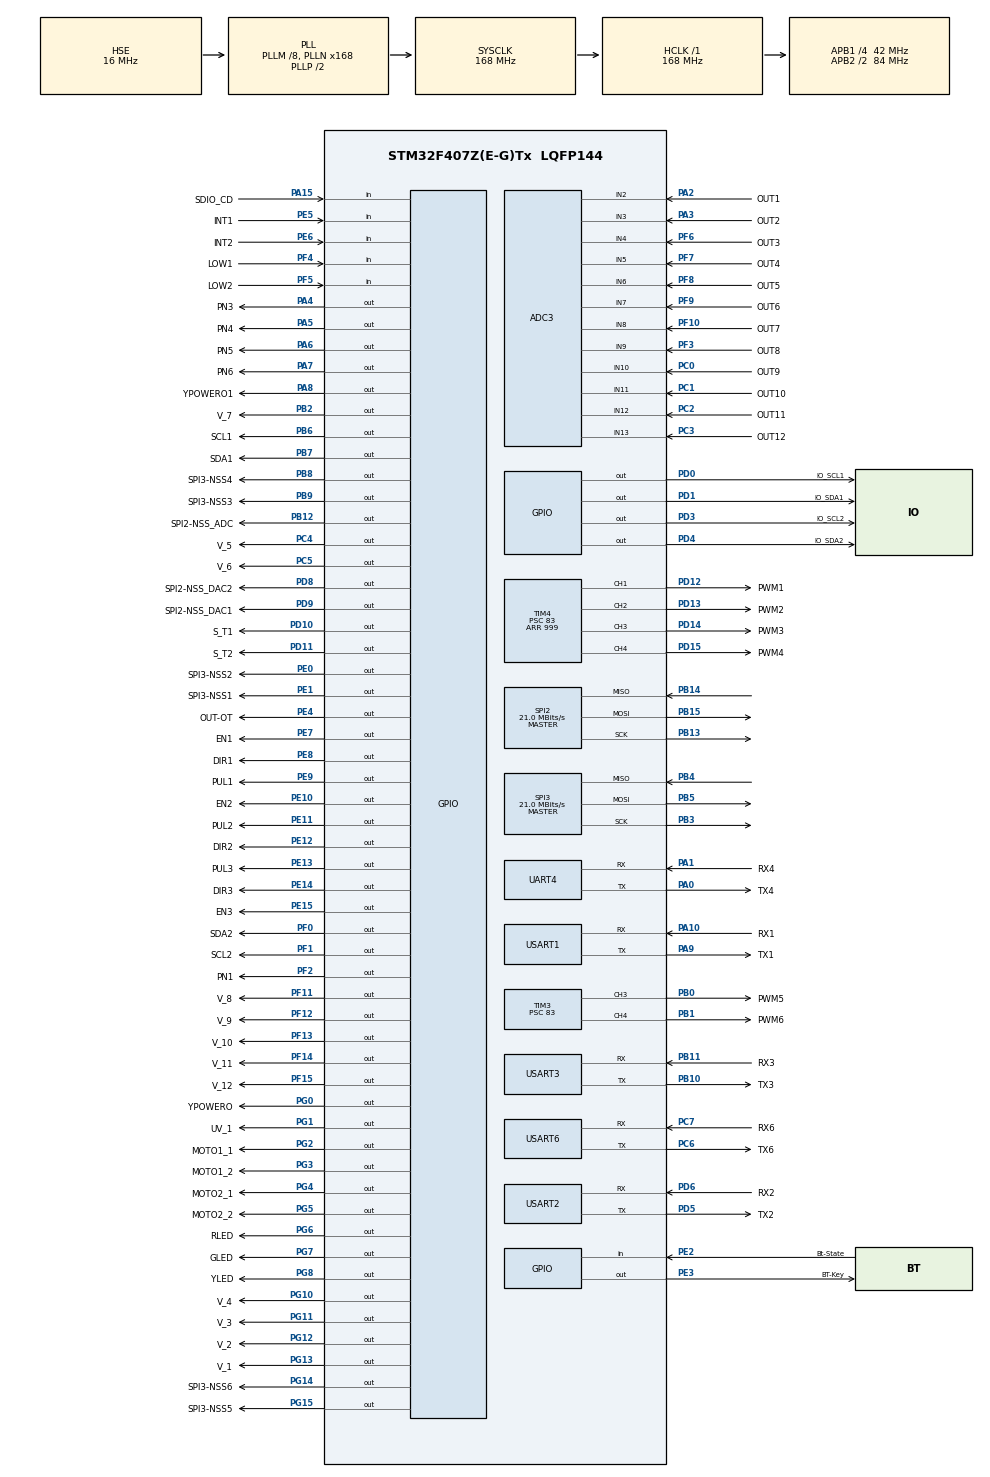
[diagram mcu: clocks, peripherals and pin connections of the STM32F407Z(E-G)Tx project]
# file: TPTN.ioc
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ADC3.Channel-0\#ChannelRegularConversion=ADC_CHANNEL_2
ADC3.Channel-1\#ChannelRegularConversion=ADC_CHANNEL_3
ADC3.Channel-10\#ChannelRegularConversion=ADC_CHANNEL_12
ADC3.Channel-11\#ChannelRegularConversion=ADC_CHANNEL_13
ADC3.Channel-2\#ChannelRegularConversion=ADC_CHANNEL_4
ADC3.Channel-3\#ChannelRegularConversion=ADC_CHANNEL_5
ADC3.Channel-4\#ChannelRegularConversion=ADC_CHANNEL_6
ADC3.Channel-5\#ChannelRegularConversion=ADC_CHANNEL_7
ADC3.Channel-6\#ChannelRegularConversion=ADC_CHANNEL_8
ADC3.Channel-7\#ChannelRegularConversion=ADC_CHANNEL_9
ADC3.Channel-8\#ChannelRegularConversion=ADC_CHANNEL_10
ADC3.Channel-9\#ChannelRegularConversion=ADC_CHANNEL_11
ADC3.DMAContinuousRequests=ENABLE
ADC3.DiscontinuousConvMode=DISABLE
ADC3.EOCSelection=ADC_EOC_SEQ_CONV
ADC3.ExternalTrigConv=ADC_EXTERNALTRIGCONV_T2_TRGO
ADC3.InjNumberOfConversion=0
ADC3.NbrOfConversion=12
ADC3.NbrOfConversionFlag=1
ADC3.Rank-0\#ChannelRegularConversion=1
ADC3.Rank-1\#ChannelRegularConversion=2
ADC3.Rank-10\#ChannelRegularConversion=11
ADC3.Rank-11\#ChannelRegularConversion=12
ADC3.Rank-2\#ChannelRegularConversion=3
ADC3.Rank-3\#ChannelRegularConversion=4
ADC3.Rank-4\#ChannelRegularConversion=5
ADC3.Rank-5\#ChannelRegularConversion=6
ADC3.Rank-6\#ChannelRegularConversion=7
ADC3.Rank-7\#ChannelRegularConversion=8
ADC3.Rank-8\#ChannelRegularConversion=9
ADC3.Rank-9\#ChannelRegularConversion=10
ADC3.SamplingTime-0\#ChannelRegularConversion=ADC_SAMPLETIME_3CYCLES
ADC3.SamplingTime-1\#ChannelRegularConversion=ADC_SAMPLETIME_3CYCLES
ADC3.SamplingTime-10\#ChannelRegularConversion=ADC_SAMPLETIME_3CYCLES
ADC3.SamplingTime-11\#ChannelRegularConversion=ADC_SAMPLETIME_3CYCLES
ADC3.SamplingTime-2\#ChannelRegularConversion=ADC_SAMPLETIME_3CYCLES
ADC3.SamplingTime-3\#ChannelRegularConversion=ADC_SAMPLETIME_3CYCLES
ADC3.SamplingTime-4\#ChannelRegularConversion=ADC_SAMPLETIME_3CYCLES
ADC3.SamplingTime-5\#ChannelRegularConversion=ADC_SAMPLETIME_3CYCLES
ADC3.SamplingTime-6\#ChannelRegularConversion=ADC_SAMPLETIME_3CYCLES
ADC3.SamplingTime-7\#ChannelRegularConversion=ADC_SAMPLETIME_3CYCLES
ADC3.SamplingTime-8\#ChannelRegularConversion=ADC_SAMPLETIME_3CYCLES
ADC3.SamplingTime-9\#ChannelRegularConversion=ADC_SAMPLETIME_3CYCLES
Dma.ADC3.2.Direction=DMA_PERIPH_TO_MEMORY
Dma.ADC3.2.FIFOMode=DMA_FIFOMODE_DISABLE
Dma.ADC3.2.Instance=DMA2_Stream0
Dma.ADC3.2.MemDataAlignment=DMA_MDATAALIGN_HALFWORD
Dma.ADC3.2.MemInc=DMA_MINC_ENABLE
Dma.ADC3.2.Mode=DMA_CIRCULAR
Dma.ADC3.2.PeriphDataAlignment=DMA_PDATAALIGN_HALFWORD
Dma.ADC3.2.PeriphInc=DMA_PINC_DISABLE
Dma.ADC3.2.Priority=DMA_PRIORITY_MEDIUM
Dma.Request0=USART3_TX
Dma.Request1=USART3_RX
Dma.Request2=ADC3
Dma.USART3_RX.1.Direction=DMA_PERIPH_TO_MEMORY
Dma.USART3_RX.1.FIFOMode=DMA_FIFOMODE_DISABLE
Dma.USART3_RX.1.Instance=DMA1_Stream1
Dma.USART3_RX.1.MemDataAlignment=DMA_MDATAALIGN_BYTE
Dma.USART3_RX.1.MemInc=DMA_MINC_ENABLE
Dma.USART3_RX.1.Mode=DMA_NORMAL
Dma.USART3_RX.1.PeriphDataAlignment=DMA_PDATAALIGN_BYTE
Dma.USART3_RX.1.PeriphInc=DMA_PINC_DISABLE
Dma.USART3_RX.1.Priority=DMA_PRIORITY_LOW
Dma.USART3_TX.0.Direction=DMA_MEMORY_TO_PERIPH
Dma.USART3_TX.0.FIFOMode=DMA_FIFOMODE_DISABLE
Dma.USART3_TX.0.Instance=DMA1_Stream3
Dma.USART3_TX.0.MemDataAlignment=DMA_MDATAALIGN_BYTE
Dma.USART3_TX.0.MemInc=DMA_MINC_ENABLE
Dma.USART3_TX.0.Mode=DMA_NORMAL
Dma.USART3_TX.0.PeriphDataAlignment=DMA_PDATAALIGN_BYTE
Dma.USART3_TX.0.PeriphInc=DMA_PINC_DISABLE
Dma.USART3_TX.0.Priority=DMA_PRIORITY_LOW
FREERTOS.Tasks01=defaultTask,0,128,StartDefaultTask,Default,NULL,Dynamic,NULL,NULL
FREERTOS.configENABLE_FPU=1
Mcu.Family=STM32F4
Mcu.Name=STM32F407Z(E-G)Tx
Mcu.Package=LQFP144
NVIC.DMA1_Stream1_IRQn=true\:6\:0\:true\:false\:true\:true\:false\:true\:true
NVIC.DMA1_Stream3_IRQn=true\:6\:0\:true\:false\:true\:true\:false\:true\:true
NVIC.DMA2_Stream0_IRQn=true\:6\:0\:true\:false\:true\:true\:false\:true\:true
NVIC.PriorityGroup=NVIC_PRIORITYGROUP_4
NVIC.TIM8_TRG_COM_TIM14_IRQn=true\:15\:0\:false\:false\:true\:false\:false\:true\:true
NVIC.TimeBase=TIM8_TRG_COM_TIM14_IRQn
NVIC.TimeBaseIP=TIM14
NVIC.USART3_IRQn=true\:6\:0\:true\:false\:true\:true\:true\:true\:true
PA0-WKUP.GPIO_Label=TX4
PA0-WKUP.Mode=Asynchronous
PA0-WKUP.Signal=UART4_TX
PA1.GPIO_Label=RX4
PA1.Mode=Asynchronous
PA1.Signal=UART4_RX
PA10.GPIO_Label=RX1
PA10.Mode=Asynchronous
PA10.Signal=USART1_RX
PA13.Mode=Serial_Wire
PA13.Signal=SYS_JTMS-SWDIO
PA14.Mode=Serial_Wire
PA14.Signal=SYS_JTCK-SWCLK
PA15.GPIO_Label=SDIO_CD
PA15.Signal=GPIO_Input
PA2.GPIO_Label=OUT1
PA2.Signal=ADCx_IN2
PA3.GPIO_Label=OUT2
PA3.Signal=ADCx_IN3
PA4.GPIO_Label=PN3
PA4.Signal=GPIO_Output
PA5.GPIO_Label=PN4
PA5.Signal=GPIO_Output
PA6.GPIO_Label=PN5
PA6.Signal=GPIO_Output
PA7.GPIO_Label=PN6
PA7.Signal=GPIO_Output
PA8.GPIO_Label=YPOWERO1
PA8.Signal=GPIO_Output
PA9.GPIO_Label=TX1
PA9.Mode=Asynchronous
PA9.Signal=USART1_TX
PB0.GPIO_Label=PWM5
PB0.Signal=S_TIM3_CH3
PB1.GPIO_Label=PWM6
PB1.Signal=S_TIM3_CH4
PB10.GPIO_Label=TX3
PB10.Mode=Asynchronous
PB10.Signal=USART3_TX
PB11.GPIO_Label=RX3
PB11.Mode=Asynchronous
PB11.Signal=USART3_RX
PB12.GPIO_Label=SPI2-NSS_ADC
PB12.Signal=GPIO_Output
PB13.Mode=Full_Duplex_Master
PB13.Signal=SPI2_SCK
PB14.Mode=Full_Duplex_Master
PB14.Signal=SPI2_MISO
PB15.Mode=Full_Duplex_Master
PB15.Signal=SPI2_MOSI
PB2.GPIO_Label=V_7
PB2.Signal=GPIO_Output
PB3.Mode=Full_Duplex_Master
PB3.Signal=SPI3_SCK
PB4.Mode=Full_Duplex_Master
PB4.Signal=SPI3_MISO
PB5.Mode=Full_Duplex_Master
PB5.Signal=SPI3_MOSI
PB6.GPIO_Label=SCL1
PB6.Signal=GPIO_Output
PB7.GPIO_Label=SDA1
PB7.GPIO_ModeDefaultOutputPP=GPIO_MODE_OUTPUT_OD
PB7.GPIO_PuPd=GPIO_PULLUP
PB7.Signal=GPIO_Output
PB8.GPIO_Label=SPI3-NSS4
PB8.Signal=GPIO_Output
PB9.GPIO_Label=SPI3-NSS3
PB9.Signal=GPIO_Output
PC0.GPIO_Label=OUT9
PC0.Signal=ADCx_IN10
PC1.GPIO_Label=OUT10
PC1.Signal=ADCx_IN11
PC10.Signal=SDIO_D2
PC11.Signal=SDIO_D3
PC12.Signal=SDIO_CK
PC14-OSC32_IN.Mode=LSE-External-Oscillator
PC14-OSC32_IN.Signal=RCC_OSC32_IN
PC15-OSC32_OUT.Mode=LSE-External-Oscillator
PC15-OSC32_OUT.Signal=RCC_OSC32_OUT
PC2.GPIO_Label=OUT11
PC2.Signal=ADCx_IN12
PC3.GPIO_Label=OUT12
PC3.Signal=ADCx_IN13
PC4.GPIO_Label=V_5
PC4.Signal=GPIO_Output
PC5.GPIO_Label=V_6
PC5.Signal=GPIO_Output
PC6.GPIO_Label=TX6
PC6.Mode=Asynchronous
PC6.Signal=USART6_TX
PC7.GPIO_Label=RX6
PC7.Mode=Asynchronous
PC7.Signal=USART6_RX
PC8.Signal=SDIO_D0
PC9.Signal=SDIO_D1
PD0.GPIO_Label=IO_SCL1
PD0.Signal=GPIO_Output
PD1.GPIO_Label=IO_SDA1
PD1.GPIO_ModeDefaultOutputPP=GPIO_MODE_OUTPUT_OD
PD1.GPIO_PuPd=GPIO_PULLUP
PD1.Signal=GPIO_Output
PD10.GPIO_Label=S_T1
PD10.Signal=GPIO_Output
PD11.GPIO_Label=S_T2
PD11.Signal=GPIO_Output
PD12.GPIO_Label=PWM1
PD12.Signal=S_TIM4_CH1
PD13.GPIO_Label=PWM2
PD13.Signal=S_TIM4_CH2
PD14.GPIO_Label=PWM3
PD14.Signal=S_TIM4_CH3
PD15.GPIO_Label=PWM4
PD15.Signal=S_TIM4_CH4
PD2.Signal=SDIO_CMD
PD3.GPIO_Label=IO_SCL2
PD3.Signal=GPIO_Output
PD4.GPIO_Label=IO_SDA2
PD4.GPIO_ModeDefaultOutputPP=GPIO_MODE_OUTPUT_OD
PD4.GPIO_PuPd=GPIO_PULLUP
PD4.Signal=GPIO_Output
PD5.GPIO_Label=TX2
PD5.Mode=Asynchronous
PD5.Signal=USART2_TX
PD6.GPIO_Label=RX2
PD6.Mode=Asynchronous
PD6.Signal=USART2_RX
PD8.GPIO_Label=SPI2-NSS_DAC2
PD8.Signal=GPIO_Output
PD9.GPIO_Label=SPI2-NSS_DAC1
PD9.Signal=GPIO_Output
PE0.GPIO_Label=SPI3-NSS2
PE0.Signal=GPIO_Output
PE1.GPIO_Label=SPI3-NSS1
PE1.Signal=GPIO_Output
PE10.GPIO_Label=EN2
PE10.Signal=GPIO_Output
PE11.GPIO_Label=PUL2
PE11.Signal=GPIO_Output
PE12.GPIO_Label=DIR2
PE12.Signal=GPIO_Output
PE13.GPIO_Label=PUL3
PE13.Signal=GPIO_Output
PE14.GPIO_Label=DIR3
PE14.Signal=GPIO_Output
PE15.GPIO_Label=EN3
PE15.Signal=GPIO_Output
PE2.GPIO_Label=Bt-State
PE2.Signal=GPIO_Input
PE3.GPIO_Label=BT-Key
PE3.Signal=GPIO_Output
PE4.GPIO_Label=OUT-OT
PE4.Signal=GPIO_Output
PE5.GPIO_Label=INT1
PE5.Signal=GPIO_Input
PE6.GPIO_Label=INT2
PE6.Signal=GPIO_Input
PE7.GPIO_Label=EN1
PE7.Signal=GPIO_Output
PE8.GPIO_Label=DIR1
PE8.Signal=GPIO_Output
PE9.GPIO_Label=PUL1
PE9.Signal=GPIO_Output
PF0.GPIO_Label=SDA2
PF0.GPIO_ModeDefaultOutputPP=GPIO_MODE_OUTPUT_OD
PF0.GPIO_PuPd=GPIO_PULLUP
PF0.Signal=GPIO_Output
PF1.GPIO_Label=SCL2
PF1.Signal=GPIO_Output
PF10.GPIO_Label=OUT7
PF10.Mode=IN8
PF10.Signal=ADC3_IN8
PF11.GPIO_Label=V_8
PF11.Signal=GPIO_Output
PF12.GPIO_Label=V_9
PF12.Signal=GPIO_Output
PF13.GPIO_Label=V_10
PF13.Signal=GPIO_Output
PF14.GPIO_Label=V_11
PF14.Signal=GPIO_Output
PF15.GPIO_Label=V_12
PF15.Signal=GPIO_Output
PF2.GPIO_Label=PN1
PF2.Signal=GPIO_Output
PF3.GPIO_Label=OUT8
PF3.Mode=IN9
PF3.Signal=ADC3_IN9
PF4.GPIO_Label=LOW1
PF4.Signal=GPIO_Input
PF5.GPIO_Label=LOW2
PF5.Signal=GPIO_Input
PF6.GPIO_Label=OUT3
PF6.Mode=IN4
PF6.Signal=ADC3_IN4
PF7.GPIO_Label=OUT4
PF7.Mode=IN5
PF7.Signal=ADC3_IN5
PF8.GPIO_Label=OUT5
PF8.Mode=IN6
PF8.Signal=ADC3_IN6
PF9.GPIO_Label=OUT6
PF9.Mode=IN7
PF9.Signal=ADC3_IN7
PG0.GPIO_Label=YPOWERO
PG0.Signal=GPIO_Output
PG1.GPIO_Label=UV_1
PG1.Signal=GPIO_Output
PG10.GPIO_Label=V_4
PG10.Signal=GPIO_Output
PG11.GPIO_Label=V_3
PG11.Signal=GPIO_Output
PG12.GPIO_Label=V_2
PG12.Signal=GPIO_Output
PG13.GPIO_Label=V_1
PG13.Signal=GPIO_Output
PG14.GPIO_Label=SPI3-NSS6
PG14.Signal=GPIO_Output
PG15.GPIO_Label=SPI3-NSS5
PG15.Signal=GPIO_Output
PG2.GPIO_Label=MOTO1_1
PG2.Signal=GPIO_Output
PG3.GPIO_Label=MOTO1_2
PG3.Signal=GPIO_Output
PG4.GPIO_Label=MOTO2_1
PG4.Signal=GPIO_Output
PG5.GPIO_Label=MOTO2_2
PG5.Signal=GPIO_Output
PG6.GPIO_Label=RLED
PG6.Signal=GPIO_Output
PG7.GPIO_Label=GLED
PG7.Signal=GPIO_Output
PG8.GPIO_Label=YLED
PG8.Signal=GPIO_Output
PH0-OSC_IN.Mode=HSE-External-Oscillator
PH0-OSC_IN.Signal=RCC_OSC_IN
PH1-OSC_OUT.Mode=HSE-External-Oscillator
PH1-OSC_OUT.Signal=RCC_OSC_OUT
ProjectManager.HeapSize=0x200
ProjectManager.StackSize=0x400
ProjectManager.TargetToolchain=MDK-ARM V5.32
RCC.48MHZClocksFreq_Value=48000000
RCC.AHBFreq_Value=168000000
RCC.APB1CLKDivider=RCC_HCLK_DIV4
RCC.APB1Freq_Value=42000000
RCC.APB1TimFreq_Value=84000000
RCC.APB2CLKDivider=RCC_HCLK_DIV2
RCC.APB2Freq_Value=84000000
RCC.APB2TimFreq_Value=168000000
RCC.CortexFreq_Value=168000000
RCC.HCLKFreq_Value=168000000
RCC.HSE_VALUE=16000000
RCC.HSI_VALUE=16000000
RCC.PLLM=8
RCC.PLLN=168
RCC.PLLQ=7
RCC.PLLSourceVirtual=RCC_PLLSOURCE_HSE
RCC.RCC_RTC_Clock_Source=RCC_RTCCLKSOURCE_LSE
RCC.RCC_RTC_Clock_SourceVirtual=RCC_RTCCLKSOURCE_LSE
RCC.SYSCLKFreq_VALUE=168000000
RCC.SYSCLKSource=RCC_SYSCLKSOURCE_PLLCLK
RCC.VCOOutputFreq_Value=336000000
SH.ADCx_IN10.0=ADC3_IN10,IN10
SH.ADCx_IN11.0=ADC3_IN11,IN11
SH.ADCx_IN12.0=ADC3_IN12,IN12
SH.ADCx_IN13.0=ADC3_IN13,IN13
SH.ADCx_IN2.0=ADC3_IN2,IN2
SH.ADCx_IN3.0=ADC3_IN3,IN3
SH.S_TIM3_CH3.0=TIM3_CH3,PWM Generation3 CH3
SH.S_TIM3_CH4.0=TIM3_CH4,PWM Generation4 CH4
SH.S_TIM4_CH1.0=TIM4_CH1,PWM Generation1 CH1
SH.S_TIM4_CH2.0=TIM4_CH2,PWM Generation2 CH2
SH.S_TIM4_CH3.0=TIM4_CH3,PWM Generation3 CH3
SH.S_TIM4_CH4.0=TIM4_CH4,PWM Generation4 CH4
SPI2.CalculateBaudRate=21.0 MBits/s
SPI2.Direction=SPI_DIRECTION_2LINES
SPI2.Mode=SPI_MODE_MASTER
SPI2.VirtualType=VM_MASTER
SPI3.CalculateBaudRate=21.0 MBits/s
SPI3.Direction=SPI_DIRECTION_2LINES
SPI3.Mode=SPI_MODE_MASTER
SPI3.VirtualType=VM_MASTER
TIM2.AutoReloadPreload=TIM_AUTORELOAD_PRELOAD_ENABLE
TIM2.Period=1000000
TIM2.Prescaler=167
TIM2.TIM_MasterOutputTrigger=TIM_TRGO_UPDATE
TIM3.AutoReloadPreload=TIM_AUTORELOAD_PRELOAD_ENABLE
TIM3.Channel-PWM\ Generation3\ CH3=TIM_CHANNEL_3
TIM3.Channel-PWM\ Generation4\ CH4=TIM_CHANNEL_4
TIM3.Period=999
TIM3.Prescaler=83
TIM4.AutoReloadPreload=TIM_AUTORELOAD_PRELOAD_ENABLE
TIM4.Channel-PWM\ Generation1\ CH1=TIM_CHANNEL_1
TIM4.Channel-PWM\ Generation2\ CH2=TIM_CHANNEL_2
TIM4.Channel-PWM\ Generation3\ CH3=TIM_CHANNEL_3
TIM4.Channel-PWM\ Generation4\ CH4=TIM_CHANNEL_4
TIM4.Period=999
TIM4.Prescaler=83
UART4.VirtualMode=Asynchronous
USART1.VirtualMode=VM_ASYNC
USART2.VirtualMode=VM_ASYNC
USART3.VirtualMode=VM_ASYNC
USART6.VirtualMode=VM_ASYNC
VP_FATFS_VS_Generic.Mode=User_defined
VP_FREERTOS_VS_CMSIS_V1.Mode=CMSIS_V1
VP_RTC_VS_RTC_Activate.Mode=RTC_Enabled
VP_SYS_VS_tim14.Mode=TIM14
VP_TIM2_VS_ClockSourceINT.Mode=Internal
VP_TIM3_VS_ClockSourceINT.Mode=Internal
VP_TIM4_VS_ClockSourceINT.Mode=Internal
board=custom

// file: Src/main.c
/* USER CODE BEGIN Header */
/**
  ******************************************************************************
  * @file           : main.c
  * @brief          : Main program body
  ******************************************************************************
  * @attention
  *
  * Copyright (c) 2026 STMicroelectronics.
  * All rights reserved.
  *
  * This software is licensed under terms that can be found in the LICENSE file
  * in the root directory of this software component.
  * If no LICENSE file comes with this software, it is provided AS-IS.
  *
  ******************************************************************************
  */
/* USER CODE END Header */
#include "main.h"
#include "cmsis_os.h"
#include "fatfs.h"

ADC_HandleTypeDef hadc3;
DMA_HandleTypeDef hdma_adc3;

RTC_HandleTypeDef hrtc;

SPI_HandleTypeDef hspi2;
SPI_HandleTypeDef hspi3;

TIM_HandleTypeDef htim2;
TIM_HandleTypeDef htim3;
TIM_HandleTypeDef htim4;

UART_HandleTypeDef huart4;
UART_HandleTypeDef huart1;
UART_HandleTypeDef huart2;
UART_HandleTypeDef huart3;
UART_HandleTypeDef huart6;
DMA_HandleTypeDef hdma_usart3_tx;
DMA_HandleTypeDef hdma_usart3_rx;

osThreadId defaultTaskHandle;

void SystemClock_Config(void);
static void MX_GPIO_Init(void);
static void MX_DMA_Init(void);
static void MX_RTC_Init(void);
static void MX_UART4_Init(void);
static void MX_TIM3_Init(void);
static void MX_USART3_UART_Init(void);
static void MX_SPI2_Init(void);
static void MX_TIM4_Init(void);
static void MX_SPI3_Init(void);
static void MX_USART1_UART_Init(void);
static void MX_USART2_UART_Init(void);
static void MX_USART6_UART_Init(void);
static void MX_ADC3_Init(void);
static void MX_TIM2_Init(void);
void StartDefaultTask(void const * argument);

int main(void)
{

  /* MCU Configuration--------------------------------------------------------*/

  /* Reset of all peripherals, Initializes the Flash interface and the Systick. */
  HAL_Init();

  /* Configure the system clock */
  SystemClock_Config();

  /* Initialize all configured peripherals */
  MX_GPIO_Init();
  MX_DMA_Init();
  MX_RTC_Init();
  MX_UART4_Init();
  MX_TIM3_Init();
  MX_USART3_UART_Init();
  MX_SPI2_Init();
  MX_TIM4_Init();
  MX_SPI3_Init();
  MX_USART1_UART_Init();
  MX_USART2_UART_Init();
  MX_USART6_UART_Init();
  MX_ADC3_Init();
  MX_FATFS_Init();
  MX_TIM2_Init();

  /* Create the thread(s) */
  /* definition and creation of defaultTask */
  osThreadDef(defaultTask, StartDefaultTask, osPriorityNormal, 0, 128);
  defaultTaskHandle = osThreadCreate(osThread(defaultTask), NULL);

  /* Start scheduler */
  osKernelStart();

  /* We should never get here as control is now taken by the scheduler */

  /* Infinite loop */
  while (1)
  {

  }
}

void SystemClock_Config(void)
{
  RCC_OscInitTypeDef RCC_OscInitStruct = {0};
  RCC_ClkInitTypeDef RCC_ClkInitStruct = {0};

  /** Configure the main internal regulator output voltage
  */
  __HAL_RCC_PWR_CLK_ENABLE();
  __HAL_PWR_VOLTAGESCALING_CONFIG(PWR_REGULATOR_VOLTAGE_SCALE1);

  /** Initializes the RCC Oscillators according to the specified parameters
  * in the RCC_OscInitTypeDef structure.
  */
  RCC_OscInitStruct.OscillatorType = RCC_OSCILLATORTYPE_HSE|RCC_OSCILLATORTYPE_LSE;
  RCC_OscInitStruct.HSEState = RCC_HSE_ON;
  RCC_OscInitStruct.LSEState = RCC_LSE_ON;
  RCC_OscInitStruct.PLL.PLLState = RCC_PLL_ON;
  RCC_OscInitStruct.PLL.PLLSource = RCC_PLLSOURCE_HSE;
  RCC_OscInitStruct.PLL.PLLM = 8;
  RCC_OscInitStruct.PLL.PLLN = 168;
  RCC_OscInitStruct.PLL.PLLP = RCC_PLLP_DIV2;
  RCC_OscInitStruct.PLL.PLLQ = 7;
  if (HAL_RCC_OscConfig(&RCC_OscInitStruct) != HAL_OK)
  {
    Error_Handler();
  }

  /** Initializes the CPU, AHB and APB buses clocks
  */
  RCC_ClkInitStruct.ClockType = RCC_CLOCKTYPE_HCLK|RCC_CLOCKTYPE_SYSCLK
                              |RCC_CLOCKTYPE_PCLK1|RCC_CLOCKTYPE_PCLK2;
  RCC_ClkInitStruct.SYSCLKSource = RCC_SYSCLKSOURCE_PLLCLK;
  RCC_ClkInitStruct.AHBCLKDivider = RCC_SYSCLK_DIV1;
  RCC_ClkInitStruct.APB1CLKDivider = RCC_HCLK_DIV4;
  RCC_ClkInitStruct.APB2CLKDivider = RCC_HCLK_DIV2;

  if (HAL_RCC_ClockConfig(&RCC_ClkInitStruct, FLASH_LATENCY_5) != HAL_OK)
  {
    Error_Handler();
  }
}

static void MX_ADC3_Init(void)
{

  ADC_ChannelConfTypeDef sConfig = {0};

  /** Configure the global features of the ADC (Clock, Resolution, Data Alignment and number of conversion)
  */
  hadc3.Instance = ADC3;
  hadc3.Init.ClockPrescaler = ADC_CLOCK_SYNC_PCLK_DIV4;
  hadc3.Init.Resolution = ADC_RESOLUTION_12B;
  hadc3.Init.ScanConvMode = ENABLE;
  hadc3.Init.ContinuousConvMode = DISABLE;
  hadc3.Init.DiscontinuousConvMode = DISABLE;
  hadc3.Init.ExternalTrigConvEdge = ADC_EXTERNALTRIGCONVEDGE_RISING;
  hadc3.Init.ExternalTrigConv = ADC_EXTERNALTRIGCONV_T2_TRGO;
  hadc3.Init.DataAlign = ADC_DATAALIGN_RIGHT;
  hadc3.Init.NbrOfConversion = 12;
  hadc3.Init.DMAContinuousRequests = ENABLE;
  hadc3.Init.EOCSelection = ADC_EOC_SEQ_CONV;
  if (HAL_ADC_Init(&hadc3) != HAL_OK)
  {
    Error_Handler();
  }

  /** Configure for the selected ADC regular channel its corresponding rank in the sequencer and its sample time.
  */
  sConfig.Channel = ADC_CHANNEL_2;
  sConfig.Rank = 1;
  sConfig.SamplingTime = ADC_SAMPLETIME_3CYCLES;
  if (HAL_ADC_ConfigChannel(&hadc3, &sConfig) != HAL_OK)
  {
    Error_Handler();
  }

  /** Configure for the selected ADC regular channel its corresponding rank in the sequencer and its sample time.
  */
  sConfig.Channel = ADC_CHANNEL_3;
  sConfig.Rank = 2;
  if (HAL_ADC_ConfigChannel(&hadc3, &sConfig) != HAL_OK)
  {
    Error_Handler();
  }

  /** Configure for the selected ADC regular channel its corresponding rank in the sequencer and its sample time.
  */
  sConfig.Channel = ADC_CHANNEL_4;
  sConfig.Rank = 3;
  if (HAL_ADC_ConfigChannel(&hadc3, &sConfig) != HAL_OK)
  {
    Error_Handler();
  }

  /** Configure for the selected ADC regular channel its corresponding rank in the sequencer and its sample time.
  */
  sConfig.Channel = ADC_CHANNEL_5;
  sConfig.Rank = 4;
  if (HAL_ADC_ConfigChannel(&hadc3, &sConfig) != HAL_OK)
  {
    Error_Handler();
  }

  /** Configure for the selected ADC regular channel its corresponding rank in the sequencer and its sample time.
  */
  sConfig.Channel = ADC_CHANNEL_6;
  sConfig.Rank = 5;
  if (HAL_ADC_ConfigChannel(&hadc3, &sConfig) != HAL_OK)
  {
    Error_Handler();
  }

  /** Configure for the selected ADC regular channel its corresponding rank in the sequencer and its sample time.
  */
  sConfig.Channel = ADC_CHANNEL_7;
  sConfig.Rank = 6;
  if (HAL_ADC_ConfigChannel(&hadc3, &sConfig) != HAL_OK)
  {
    Error_Handler();
  }

  /** Configure for the selected ADC regular channel its corresponding rank in the sequencer and its sample time.
  */
  sConfig.Channel = ADC_CHANNEL_8;
  sConfig.Rank = 7;
  if (HAL_ADC_ConfigChannel(&hadc3, &sConfig) != HAL_OK)
  {
    Error_Handler();
  }

  /** Configure for the selected ADC regular channel its corresponding rank in the sequencer and its sample time.
  */
  sConfig.Channel = ADC_CHANNEL_9;
  sConfig.Rank = 8;
  if (HAL_ADC_ConfigChannel(&hadc3, &sConfig) != HAL_OK)
  {
    Error_Handler();
  }

  /** Configure for the selected ADC regular channel its corresponding rank in the sequencer and its sample time.
  */
  sConfig.Channel = ADC_CHANNEL_10;
  sConfig.Rank = 9;
  if (HAL_ADC_ConfigChannel(&hadc3, &sConfig) != HAL_OK)
  {
    Error_Handler();
  }

  /** Configure for the selected ADC regular channel its corresponding rank in the sequencer and its sample time.
  */
  sConfig.Channel = ADC_CHANNEL_11;
  sConfig.Rank = 10;
  if (HAL_ADC_ConfigChannel(&hadc3, &sConfig) != HAL_OK)
  {
    Error_Handler();
  }

  /** Configure for the selected ADC regular channel its corresponding rank in the sequencer and its sample time.
  */
  sConfig.Channel = ADC_CHANNEL_12;
  sConfig.Rank = 11;
  if (HAL_ADC_ConfigChannel(&hadc3, &sConfig) != HAL_OK)
  {
    Error_Handler();
  }

  /** Configure for the selected ADC regular channel its corresponding rank in the sequencer and its sample time.
  */
  sConfig.Channel = ADC_CHANNEL_13;
  sConfig.Rank = 12;
  if (HAL_ADC_ConfigChannel(&hadc3, &sConfig) != HAL_OK)
  {
    Error_Handler();
  }

}

static void MX_RTC_Init(void)
{

  /** Initialize RTC Only
  */
  hrtc.Instance = RTC;
  hrtc.Init.HourFormat = RTC_HOURFORMAT_24;
  hrtc.Init.AsynchPrediv = 127;
  hrtc.Init.SynchPrediv = 255;
  hrtc.Init.OutPut = RTC_OUTPUT_DISABLE;
  hrtc.Init.OutPutPolarity = RTC_OUTPUT_POLARITY_HIGH;
  hrtc.Init.OutPutType = RTC_OUTPUT_TYPE_OPENDRAIN;
  if (HAL_RTC_Init(&hrtc) != HAL_OK)
  {
    Error_Handler();
  }

}

static void MX_SPI2_Init(void)
{

  /* SPI2 parameter configuration*/
  hspi2.Instance = SPI2;
  hspi2.Init.Mode = SPI_MODE_MASTER;
  hspi2.Init.Direction = SPI_DIRECTION_2LINES;
  hspi2.Init.DataSize = SPI_DATASIZE_8BIT;
  hspi2.Init.CLKPolarity = SPI_POLARITY_LOW;
  hspi2.Init.CLKPhase = SPI_PHASE_1EDGE;
  hspi2.Init.NSS = SPI_NSS_SOFT;
  hspi2.Init.BaudRatePrescaler = SPI_BAUDRATEPRESCALER_2;
  hspi2.Init.FirstBit = SPI_FIRSTBIT_MSB;
  hspi2.Init.TIMode = SPI_TIMODE_DISABLE;
  hspi2.Init.CRCCalculation = SPI_CRCCALCULATION_DISABLE;
  hspi2.Init.CRCPolynomial = 10;
  if (HAL_SPI_Init(&hspi2) != HAL_OK)
  {
    Error_Handler();
  }

}

static void MX_SPI3_Init(void)
{

  /* SPI3 parameter configuration*/
  hspi3.Instance = SPI3;
  hspi3.Init.Mode = SPI_MODE_MASTER;
  hspi3.Init.Direction = SPI_DIRECTION_2LINES;
  hspi3.Init.DataSize = SPI_DATASIZE_8BIT;
  hspi3.Init.CLKPolarity = SPI_POLARITY_LOW;
  hspi3.Init.CLKPhase = SPI_PHASE_1EDGE;
  hspi3.Init.NSS = SPI_NSS_SOFT;
  hspi3.Init.BaudRatePrescaler = SPI_BAUDRATEPRESCALER_2;
  hspi3.Init.FirstBit = SPI_FIRSTBIT_MSB;
  hspi3.Init.TIMode = SPI_TIMODE_DISABLE;
  hspi3.Init.CRCCalculation = SPI_CRCCALCULATION_DISABLE;
  hspi3.Init.CRCPolynomial = 10;
  if (HAL_SPI_Init(&hspi3) != HAL_OK)
  {
    Error_Handler();
  }

}

static void MX_TIM2_Init(void)
{

  TIM_ClockConfigTypeDef sClockSourceConfig = {0};
  TIM_MasterConfigTypeDef sMasterConfig = {0};

  htim2.Instance = TIM2;
  htim2.Init.Prescaler = 167;
  htim2.Init.CounterMode = TIM_COUNTERMODE_UP;
  htim2.Init.Period = 1000000;
  htim2.Init.ClockDivision = TIM_CLOCKDIVISION_DIV1;
  htim2.Init.AutoReloadPreload = TIM_AUTORELOAD_PRELOAD_ENABLE;
  if (HAL_TIM_Base_Init(&htim2) != HAL_OK)
  {
    Error_Handler();
  }
  sClockSourceConfig.ClockSource = TIM_CLOCKSOURCE_INTERNAL;
  if (HAL_TIM_ConfigClockSource(&htim2, &sClockSourceConfig) != HAL_OK)
  {
    Error_Handler();
  }
  sMasterConfig.MasterOutputTrigger = TIM_TRGO_UPDATE;
  sMasterConfig.MasterSlaveMode = TIM_MASTERSLAVEMODE_DISABLE;
  if (HAL_TIMEx_MasterConfigSynchronization(&htim2, &sMasterConfig) != HAL_OK)
  {
    Error_Handler();
  }

}

static void MX_TIM3_Init(void)
{

  TIM_ClockConfigTypeDef sClockSourceConfig = {0};
  TIM_MasterConfigTypeDef sMasterConfig = {0};
  TIM_OC_InitTypeDef sConfigOC = {0};

  htim3.Instance = TIM3;
  htim3.Init.Prescaler = 83;
  htim3.Init.CounterMode = TIM_COUNTERMODE_UP;
  htim3.Init.Period = 999;
  htim3.Init.ClockDivision = TIM_CLOCKDIVISION_DIV1;
  htim3.Init.AutoReloadPreload = TIM_AUTORELOAD_PRELOAD_ENABLE;
  if (HAL_TIM_Base_Init(&htim3) != HAL_OK)
  {
    Error_Handler();
  }
  sClockSourceConfig.ClockSource = TIM_CLOCKSOURCE_INTERNAL;
  if (HAL_TIM_ConfigClockSource(&htim3, &sClockSourceConfig) != HAL_OK)
  {
    Error_Handler();
  }
  if (HAL_TIM_PWM_Init(&htim3) != HAL_OK)
  {
    Error_Handler();
  }
  sMasterConfig.MasterOutputTrigger = TIM_TRGO_RESET;
  sMasterConfig.MasterSlaveMode = TIM_MASTERSLAVEMODE_DISABLE;
  if (HAL_TIMEx_MasterConfigSynchronization(&htim3, &sMasterConfig) != HAL_OK)
  {
    Error_Handler();
  }
  sConfigOC.OCMode = TIM_OCMODE_PWM1;
  sConfigOC.Pulse = 0;
  sConfigOC.OCPolarity = TIM_OCPOLARITY_HIGH;
  sConfigOC.OCFastMode = TIM_OCFAST_DISABLE;
  if (HAL_TIM_PWM_ConfigChannel(&htim3, &sConfigOC, TIM_CHANNEL_3) != HAL_OK)
  {
    Error_Handler();
  }
  if (HAL_TIM_PWM_ConfigChannel(&htim3, &sConfigOC, TIM_CHANNEL_4) != HAL_OK)
  {
    Error_Handler();
  }
  HAL_TIM_MspPostInit(&htim3);

}

static void MX_TIM4_Init(void)
{

  TIM_ClockConfigTypeDef sClockSourceConfig = {0};
  TIM_MasterConfigTypeDef sMasterConfig = {0};
  TIM_OC_InitTypeDef sConfigOC = {0};

  htim4.Instance = TIM4;
  htim4.Init.Prescaler = 83;
  htim4.Init.CounterMode = TIM_COUNTERMODE_UP;
  htim4.Init.Period = 999;
  htim4.Init.ClockDivision = TIM_CLOCKDIVISION_DIV1;
  htim4.Init.AutoReloadPreload = TIM_AUTORELOAD_PRELOAD_ENABLE;
  if (HAL_TIM_Base_Init(&htim4) != HAL_OK)
  {
    Error_Handler();
  }
  sClockSourceConfig.ClockSource = TIM_CLOCKSOURCE_INTERNAL;
  if (HAL_TIM_ConfigClockSource(&htim4, &sClockSourceConfig) != HAL_OK)
  {
    Error_Handler();
  }
  if (HAL_TIM_PWM_Init(&htim4) != HAL_OK)
  {
    Error_Handler();
  }
  sMasterConfig.MasterOutputTrigger = TIM_TRGO_RESET;
  sMasterConfig.MasterSlaveMode = TIM_MASTERSLAVEMODE_DISABLE;
  if (HAL_TIMEx_MasterConfigSynchronization(&htim4, &sMasterConfig) != HAL_OK)
  {
    Error_Handler();
  }
  sConfigOC.OCMode = TIM_OCMODE_PWM1;
  sConfigOC.Pulse = 0;
  sConfigOC.OCPolarity = TIM_OCPOLARITY_HIGH;
  sConfigOC.OCFastMode = TIM_OCFAST_DISABLE;
  if (HAL_TIM_PWM_ConfigChannel(&htim4, &sConfigOC, TIM_CHANNEL_1) != HAL_OK)
  {
    Error_Handler();
  }
  if (HAL_TIM_PWM_ConfigChannel(&htim4, &sConfigOC, TIM_CHANNEL_2) != HAL_OK)
  {
    Error_Handler();
  }
  if (HAL_TIM_PWM_ConfigChannel(&htim4, &sConfigOC, TIM_CHANNEL_3) != HAL_OK)
  {
    Error_Handler();
  }
  if (HAL_TIM_PWM_ConfigChannel(&htim4, &sConfigOC, TIM_CHANNEL_4) != HAL_OK)
  {
    Error_Handler();
  }
  HAL_TIM_MspPostInit(&htim4);

}

static void MX_UART4_Init(void)
{

  huart4.Instance = UART4;
  huart4.Init.BaudRate = 115200;
  huart4.Init.WordLength = UART_WORDLENGTH_8B;
  huart4.Init.StopBits = UART_STOPBITS_1;
  huart4.Init.Parity = UART_PARITY_NONE;
  huart4.Init.Mode = UART_MODE_TX_RX;
  huart4.Init.HwFlowCtl = UART_HWCONTROL_NONE;
  huart4.Init.OverSampling = UART_OVERSAMPLING_16;
  if (HAL_UART_Init(&huart4) != HAL_OK)
  {
    Error_Handler();
  }

}

static void MX_USART1_UART_Init(void)
{

  huart1.Instance = USART1;
  huart1.Init.BaudRate = 115200;
  huart1.Init.WordLength = UART_WORDLENGTH_8B;
  huart1.Init.StopBits = UART_STOPBITS_1;
  huart1.Init.Parity = UART_PARITY_NONE;
  huart1.Init.Mode = UART_MODE_TX_RX;
  huart1.Init.HwFlowCtl = UART_HWCONTROL_NONE;
  huart1.Init.OverSampling = UART_OVERSAMPLING_16;
  if (HAL_UART_Init(&huart1) != HAL_OK)
  {
    Error_Handler();
  }

}

static void MX_USART2_UART_Init(void)
{

  huart2.Instance = USART2;
  huart2.Init.BaudRate = 115200;
  huart2.Init.WordLength = UART_WORDLENGTH_8B;
  huart2.Init.StopBits = UART_STOPBITS_1;
  huart2.Init.Parity = UART_PARITY_NONE;
  huart2.Init.Mode = UART_MODE_TX_RX;
  huart2.Init.HwFlowCtl = UART_HWCONTROL_NONE;
  huart2.Init.OverSampling = UART_OVERSAMPLING_16;
  if (HAL_UART_Init(&huart2) != HAL_OK)
  {
    Error_Handler();
  }

}

static void MX_USART3_UART_Init(void)
{

  huart3.Instance = USART3;
  huart3.Init.BaudRate = 115200;
  huart3.Init.WordLength = UART_WORDLENGTH_8B;
  huart3.Init.StopBits = UART_STOPBITS_1;
  huart3.Init.Parity = UART_PARITY_NONE;
  huart3.Init.Mode = UART_MODE_TX_RX;
  huart3.Init.HwFlowCtl = UART_HWCONTROL_NONE;
  huart3.Init.OverSampling = UART_OVERSAMPLING_16;
  if (HAL_UART_Init(&huart3) != HAL_OK)
  {
    Error_Handler();
  }

}

static void MX_USART6_UART_Init(void)
{

  huart6.Instance = USART6;
  huart6.Init.BaudRate = 115200;
  huart6.Init.WordLength = UART_WORDLENGTH_8B;
  huart6.Init.StopBits = UART_STOPBITS_1;
  huart6.Init.Parity = UART_PARITY_NONE;
  huart6.Init.Mode = UART_MODE_TX_RX;
  huart6.Init.HwFlowCtl = UART_HWCONTROL_NONE;
  huart6.Init.OverSampling = UART_OVERSAMPLING_16;
  if (HAL_UART_Init(&huart6) != HAL_OK)
  {
    Error_Handler();
  }

}

static void MX_DMA_Init(void)
{

  /* DMA controller clock enable */
  __HAL_RCC_DMA1_CLK_ENABLE();
  __HAL_RCC_DMA2_CLK_ENABLE();

  /* DMA interrupt init */
  /* DMA1_Stream1_IRQn interrupt configuration */
  HAL_NVIC_SetPriority(DMA1_Stream1_IRQn, 6, 0);
  HAL_NVIC_EnableIRQ(DMA1_Stream1_IRQn);
  /* DMA1_Stream3_IRQn interrupt configuration */
  HAL_NVIC_SetPriority(DMA1_Stream3_IRQn, 6, 0);
  HAL_NVIC_EnableIRQ(DMA1_Stream3_IRQn);
  /* DMA2_Stream0_IRQn interrupt configuration */
  HAL_NVIC_SetPriority(DMA2_Stream0_IRQn, 6, 0);
  HAL_NVIC_EnableIRQ(DMA2_Stream0_IRQn);

}

static void MX_GPIO_Init(void)
{
  GPIO_InitTypeDef GPIO_InitStruct = {0};

  /* GPIO Ports Clock Enable */
  __HAL_RCC_GPIOE_CLK_ENABLE();
  __HAL_RCC_GPIOC_CLK_ENABLE();
  __HAL_RCC_GPIOF_CLK_ENABLE();
  __HAL_RCC_GPIOH_CLK_ENABLE();
  __HAL_RCC_GPIOA_CLK_ENABLE();
  __HAL_RCC_GPIOB_CLK_ENABLE();
  __HAL_RCC_GPIOG_CLK_ENABLE();
  __HAL_RCC_GPIOD_CLK_ENABLE();

  /*Configure GPIO pin Output Level */
  HAL_GPIO_WritePin(GPIOE, BT_Key_Pin|OUT_OT_Pin|EN1_Pin|DIR1_Pin
                          |PUL1_Pin|EN2_Pin|PUL2_Pin|DIR2_Pin
                          |PUL3_Pin|DIR3_Pin|EN3_Pin|SPI3_NSS2_Pin
                          |SPI3_NSS1_Pin, GPIO_PIN_RESET);

  /*Configure GPIO pin Output Level */
  HAL_GPIO_WritePin(GPIOF, SDA2_Pin|SCL2_Pin|PN1_Pin|V_8_Pin
                          |V_9_Pin|V_10_Pin|V_11_Pin|V_12_Pin, GPIO_PIN_RESET);

  /*Configure GPIO pin Output Level */
  HAL_GPIO_WritePin(GPIOA, PN3_Pin|PN4_Pin|PN5_Pin|PN6_Pin
                          |YPOWERO1_Pin, GPIO_PIN_RESET);

  /*Configure GPIO pin Output Level */
  HAL_GPIO_WritePin(GPIOC, V_5_Pin|V_6_Pin, GPIO_PIN_RESET);

  /*Configure GPIO pin Output Level */
  HAL_GPIO_WritePin(GPIOB, V_7_Pin|SPI2_NSS_ADC_Pin|SCL1_Pin|SDA1_Pin
                          |SPI3_NSS4_Pin|SPI3_NSS3_Pin, GPIO_PIN_RESET);

  /*Configure GPIO pin Output Level */
  HAL_GPIO_WritePin(GPIOG, YPOWERO_Pin|UV_1_Pin|MOTO1_1_Pin|MOTO1_2_Pin
                          |MOTO2_1_Pin|MOTO2_2_Pin|RLED_Pin|GLED_Pin
                          |YLED_Pin|V_4_Pin|V_3_Pin|V_2_Pin
                          |V_1_Pin|SPI3_NSS6_Pin|SPI3_NSS5_Pin, GPIO_PIN_RESET);

  /*Configure GPIO pin Output Level */
  HAL_GPIO_WritePin(GPIOD, SPI2_NSS_DAC2_Pin|SPI2_NSS_DAC1_Pin|S_T1_Pin|S_T2_Pin
                          |IO_SCL1_Pin|IO_SDA1_Pin|IO_SCL2_Pin|IO_SDA2_Pin, GPIO_PIN_RESET);

  /*Configure GPIO pins : Bt_State_Pin INT1_Pin INT2_Pin */
  GPIO_InitStruct.Pin = Bt_State_Pin|INT1_Pin|INT2_Pin;
  GPIO_InitStruct.Mode = GPIO_MODE_INPUT;
  GPIO_InitStruct.Pull = GPIO_NOPULL;
  HAL_GPIO_Init(GPIOE, &GPIO_InitStruct);

  /*Configure GPIO pins : BT_Key_Pin OUT_OT_Pin EN1_Pin DIR1_Pin
                           PUL1_Pin EN2_Pin PUL2_Pin DIR2_Pin
                           PUL3_Pin DIR3_Pin EN3_Pin SPI3_NSS2_Pin
                           SPI3_NSS1_Pin */
  GPIO_InitStruct.Pin = BT_Key_Pin|OUT_OT_Pin|EN1_Pin|DIR1_Pin
                          |PUL1_Pin|EN2_Pin|PUL2_Pin|DIR2_Pin
                          |PUL3_Pin|DIR3_Pin|EN3_Pin|SPI3_NSS2_Pin
                          |SPI3_NSS1_Pin;
  GPIO_InitStruct.Mode = GPIO_MODE_OUTPUT_PP;
  GPIO_InitStruct.Pull = GPIO_NOPULL;
  GPIO_InitStruct.Speed = GPIO_SPEED_FREQ_LOW;
  HAL_GPIO_Init(GPIOE, &GPIO_InitStruct);

  /*Configure GPIO pin : SDA2_Pin */
  GPIO_InitStruct.Pin = SDA2_Pin;
  GPIO_InitStruct.Mode = GPIO_MODE_OUTPUT_OD;
  GPIO_InitStruct.Pull = GPIO_PULLUP;
  GPIO_InitStruct.Speed = GPIO_SPEED_FREQ_LOW;
  HAL_GPIO_Init(SDA2_GPIO_Port, &GPIO_InitStruct);

  /*Configure GPIO pins : SCL2_Pin PN1_Pin V_8_Pin V_9_Pin
                           V_10_Pin V_11_Pin V_12_Pin */
  GPIO_InitStruct.Pin = SCL2_Pin|PN1_Pin|V_8_Pin|V_9_Pin
                          |V_10_Pin|V_11_Pin|V_12_Pin;
  GPIO_InitStruct.Mode = GPIO_MODE_OUTPUT_PP;
  GPIO_InitStruct.Pull = GPIO_NOPULL;
  GPIO_InitStruct.Speed = GPIO_SPEED_FREQ_LOW;
  HAL_GPIO_Init(GPIOF, &GPIO_InitStruct);

  /*Configure GPIO pins : LOW1_Pin LOW2_Pin */
  GPIO_InitStruct.Pin = LOW1_Pin|LOW2_Pin;
  GPIO_InitStruct.Mode = GPIO_MODE_INPUT;
  GPIO_InitStruct.Pull = GPIO_NOPULL;
  HAL_GPIO_Init(GPIOF, &GPIO_InitStruct);

  /*Configure GPIO pins : PN3_Pin PN4_Pin PN5_Pin PN6_Pin
                           YPOWERO1_Pin */
  GPIO_InitStruct.Pin = PN3_Pin|PN4_Pin|PN5_Pin|PN6_Pin
                          |YPOWERO1_Pin;
  GPIO_InitStruct.Mode = GPIO_MODE_OUTPUT_PP;
  GPIO_InitStruct.Pull = GPIO_NOPULL;
  GPIO_InitStruct.Speed = GPIO_SPEED_FREQ_LOW;
  HAL_GPIO_Init(GPIOA, &GPIO_InitStruct);

  /*Configure GPIO pins : V_5_Pin V_6_Pin */
  GPIO_InitStruct.Pin = V_5_Pin|V_6_Pin;
  GPIO_InitStruct.Mode = GPIO_MODE_OUTPUT_PP;
  GPIO_InitStruct.Pull = GPIO_NOPULL;
  GPIO_InitStruct.Speed = GPIO_SPEED_FREQ_LOW;
  HAL_GPIO_Init(GPIOC, &GPIO_InitStruct);

  /*Configure GPIO pins : V_7_Pin SPI2_NSS_ADC_Pin SCL1_Pin SPI3_NSS4_Pin
                           SPI3_NSS3_Pin */
  GPIO_InitStruct.Pin = V_7_Pin|SPI2_NSS_ADC_Pin|SCL1_Pin|SPI3_NSS4_Pin
                          |SPI3_NSS3_Pin;
  GPIO_InitStruct.Mode = GPIO_MODE_OUTPUT_PP;
  GPIO_InitStruct.Pull = GPIO_NOPULL;
  GPIO_InitStruct.Speed = GPIO_SPEED_FREQ_LOW;
  HAL_GPIO_Init(GPIOB, &GPIO_InitStruct);

  /*Configure GPIO pins : YPOWERO_Pin UV_1_Pin MOTO1_1_Pin MOTO1_2_Pin
                           MOTO2_1_Pin MOTO2_2_Pin RLED_Pin GLED_Pin
                           YLED_Pin V_4_Pin V_3_Pin V_2_Pin
                           V_1_Pin SPI3_NSS6_Pin SPI3_NSS5_Pin */
  GPIO_InitStruct.Pin = YPOWERO_Pin|UV_1_Pin|MOTO1_1_Pin|MOTO1_2_Pin
                          |MOTO2_1_Pin|MOTO2_2_Pin|RLED_Pin|GLED_Pin
                          |YLED_Pin|V_4_Pin|V_3_Pin|V_2_Pin
                          |V_1_Pin|SPI3_NSS6_Pin|SPI3_NSS5_Pin;
  GPIO_InitStruct.Mode = GPIO_MODE_OUTPUT_PP;
  GPIO_InitStruct.Pull = GPIO_NOPULL;
  GPIO_InitStruct.Speed = GPIO_SPEED_FREQ_LOW;
  HAL_GPIO_Init(GPIOG, &GPIO_InitStruct);

  /*Configure GPIO pins : SPI2_NSS_DAC2_Pin SPI2_NSS_DAC1_Pin S_T1_Pin S_T2_Pin
                           IO_SCL1_Pin IO_SCL2_Pin */
  GPIO_InitStruct.Pin = SPI2_NSS_DAC2_Pin|SPI2_NSS_DAC1_Pin|S_T1_Pin|S_T2_Pin
                          |IO_SCL1_Pin|IO_SCL2_Pin;
  GPIO_InitStruct.Mode = GPIO_MODE_OUTPUT_PP;
  GPIO_InitStruct.Pull = GPIO_NOPULL;
  GPIO_InitStruct.Speed = GPIO_SPEED_FREQ_LOW;
  HAL_GPIO_Init(GPIOD, &GPIO_InitStruct);

  /*Configure GPIO pins : PC8 PC9 PC10 PC11
                           PC12 */
  GPIO_InitStruct.Pin = GPIO_PIN_8|GPIO_PIN_9|GPIO_PIN_10|GPIO_PIN_11
                          |GPIO_PIN_12;
  GPIO_InitStruct.Mode = GPIO_MODE_AF_PP;
  GPIO_InitStruct.Pull = GPIO_NOPULL;
  GPIO_InitStruct.Speed = GPIO_SPEED_FREQ_VERY_HIGH;
  GPIO_InitStruct.Alternate = GPIO_AF12_SDIO;
  HAL_GPIO_Init(GPIOC, &GPIO_InitStruct);

  /*Configure GPIO pin : SDIO_CD_Pin */
  GPIO_InitStruct.Pin = SDIO_CD_Pin;
  GPIO_InitStruct.Mode = GPIO_MODE_INPUT;
  GPIO_InitStruct.Pull = GPIO_NOPULL;
  HAL_GPIO_Init(SDIO_CD_GPIO_Port, &GPIO_InitStruct);

  /*Configure GPIO pins : IO_SDA1_Pin IO_SDA2_Pin */
  GPIO_InitStruct.Pin = IO_SDA1_Pin|IO_SDA2_Pin;
  GPIO_InitStruct.Mode = GPIO_MODE_OUTPUT_OD;
  GPIO_InitStruct.Pull = GPIO_PULLUP;
  GPIO_InitStruct.Speed = GPIO_SPEED_FREQ_LOW;
  HAL_GPIO_Init(GPIOD, &GPIO_InitStruct);

  /*Configure GPIO pin : PD2 */
  GPIO_InitStruct.Pin = GPIO_PIN_2;
  GPIO_InitStruct.Mode = GPIO_MODE_AF_PP;
  GPIO_InitStruct.Pull = GPIO_NOPULL;
  GPIO_InitStruct.Speed = GPIO_SPEED_FREQ_VERY_HIGH;
  GPIO_InitStruct.Alternate = GPIO_AF12_SDIO;
  HAL_GPIO_Init(GPIOD, &GPIO_InitStruct);

  /*Configure GPIO pin : SDA1_Pin */
  GPIO_InitStruct.Pin = SDA1_Pin;
  GPIO_InitStruct.Mode = GPIO_MODE_OUTPUT_OD;
  GPIO_InitStruct.Pull = GPIO_PULLUP;
  GPIO_InitStruct.Speed = GPIO_SPEED_FREQ_LOW;
  HAL_GPIO_Init(SDA1_GPIO_Port, &GPIO_InitStruct);

}

/* USER CODE BEGIN Header_StartDefaultTask */
/**
  * @brief  Function implementing the defaultTask thread.
  * @param  argument: Not used
  * @retval None
  */

#define ADC_CHANNEL_COUNT 12
uint16_t adc_buffer[ADC_CHANNEL_COUNT];

/* USER CODE END Header_StartDefaultTask */
void StartDefaultTask(void const * argument)
{
  /* USER CODE BEGIN 5 */
	sbUsart_Init();
	HAL_TIM_Base_Start(&htim2);
	HAL_ADC_Start_DMA(&hadc3, (uint32_t*)adc_buffer, ADC_CHANNEL_COUNT);

	HAL_TIM_PWM_Start(&htim3, TIM_CHANNEL_3);  // ���� CH3
  HAL_TIM_PWM_Start(&htim3, TIM_CHANNEL_4);  // ���� CH4

	HAL_TIM_PWM_Start(&htim4, TIM_CHANNEL_1);  // ���� CH3
  HAL_TIM_PWM_Start(&htim4, TIM_CHANNEL_2);  // ���� CH4
	HAL_TIM_PWM_Start(&htim4, TIM_CHANNEL_3);  // ���� CH3
  HAL_TIM_PWM_Start(&htim4, TIM_CHANNEL_4);  // ���� CH4

	__HAL_TIM_SET_COMPARE(&htim3, TIM_CHANNEL_3, 300);  // ռ�ձ� 30%
  __HAL_TIM_SET_COMPARE(&htim3, TIM_CHANNEL_4, 700);  // ռ�ձ� 70%

  __HAL_TIM_SET_COMPARE(&htim4, TIM_CHANNEL_1, 200);  // ռ�ձ� 30%
  __HAL_TIM_SET_COMPARE(&htim4, TIM_CHANNEL_2, 300);  // ռ�ձ� 70%
	__HAL_TIM_SET_COMPARE(&htim4, TIM_CHANNEL_3, 400);  // ռ�ձ� 30%
  __HAL_TIM_SET_COMPARE(&htim4, TIM_CHANNEL_4, 500);  // ռ�ձ� 70%

  /* Infinite loop */
  for(;;)
  {
    osDelay(1000);
		UsartDriver_SendData(USART3 , "1235\r\n",5,1000);
		  osDelay(1000);
			UsartDriver_SendData(USART3 , "1236\r\n",5,1000);
		__nop();
  }
  /* USER CODE END 5 */
}

void HAL_TIM_PeriodElapsedCallback(TIM_HandleTypeDef *htim)
{
  if (htim->Instance == TIM14)
  {
    HAL_IncTick();
  }
}

void Error_Handler(void)
{
  __disable_irq();
  while (1)
  {
  }
}
